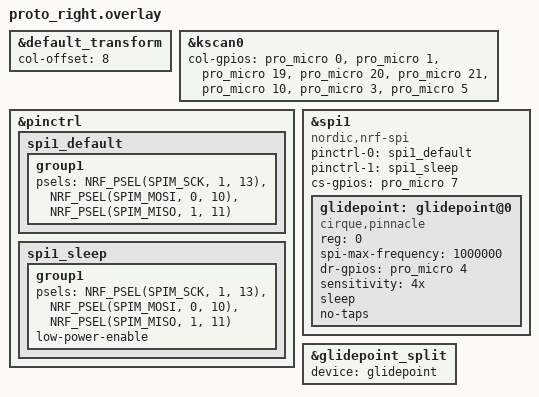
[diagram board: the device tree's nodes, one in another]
#include "proto.dtsi" // Notice that the main dtsi files are included in the overlay.

&default_transform { // The matrix transform for this board is 6 columns over because the left half is 6 columns wide according to the matrix.
    col-offset = <8>;
};

&kscan0 {
    col-gpios
        = <&pro_micro 0 GPIO_ACTIVE_HIGH> // col0 in the schematic
        , <&pro_micro 1 GPIO_ACTIVE_HIGH> // col1 in the schematic
        , <&pro_micro 19 GPIO_ACTIVE_HIGH> // col2 in the schematic
        , <&pro_micro 20 GPIO_ACTIVE_HIGH> // col3 in the schematic
        , <&pro_micro 21 GPIO_ACTIVE_HIGH> // col4 in the schematic
        , <&pro_micro 10 GPIO_ACTIVE_HIGH> // col5 in the schematic
        , <&pro_micro 3 GPIO_ACTIVE_HIGH> // col6 in the schematic
        , <&pro_micro 5 GPIO_ACTIVE_HIGH> // col7 in the schematic
        ;
};

// ----- Pointing device

&pinctrl {
    spi1_default: spi1_default {
        group1 {
            psels = <NRF_PSEL(SPIM_SCK, 1, 13)>,
                <NRF_PSEL(SPIM_MOSI, 0, 10)>,
                <NRF_PSEL(SPIM_MISO, 1, 11)>;
        };
    };

    spi1_sleep: spi1_sleep {
        group1 {
            psels = <NRF_PSEL(SPIM_SCK, 1, 13)>,
                <NRF_PSEL(SPIM_MOSI, 0, 10)>,
                <NRF_PSEL(SPIM_MISO, 1, 11)>;
            low-power-enable;
        };
    };
};

&spi1 {
    compatible = "nordic,nrf-spi";
    status = "okay";
    pinctrl-0 = <&spi1_default>;
    pinctrl-1 = <&spi1_sleep>;
    pinctrl-names = "default", "sleep";

    cs-gpios = <&pro_micro 7 GPIO_ACTIVE_HIGH>;

    glidepoint: glidepoint@0 {
        compatible = "cirque,pinnacle";
        reg = <0>;
        spi-max-frequency = <1000000>;
        status = "okay";
        dr-gpios = <&pro_micro 4 (GPIO_ACTIVE_HIGH)>;

        sensitivity = "4x";
        sleep;
        no-taps;
    };
};

pro_micro_spi: &spi1 {};

&glidepoint_split {
    device = <&glidepoint>;

    // Optional
    // input-processors = <&zip_xy_transform (INPUT_TRANSFORM_XY_SWAP | INPUT_TRANSFORM_X_INVERT | INPUT_TRANSFORM_Y_INVERT)>;
};

// ----- Pointing device end
